AUTOSAR XML (schema 4-2-2)
package /ASW_COM_STD_Package
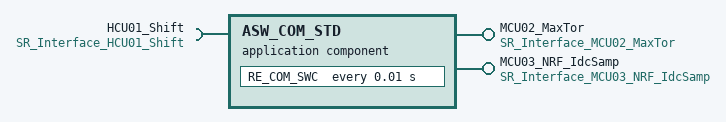
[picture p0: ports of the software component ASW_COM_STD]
  application sw component type ASW_COM_STD
    provide port MCU02_MaxTor: provided-interface=SR_Interface_MCU02_MaxTor
    provide port MCU03_NRF_IdcSamp: provided-interface=SR_Interface_MCU03_NRF_IdcSamp
    require port HCU01_Shift: nonqueued-receiver-com-spec{data-element=HCU01_Shift, alive-timeout=0.3, filter=data-filter-type=ALWAYS}, required-interface=SR_Interface_HCU01_Shift
    behavior ASW_COM_STD_InternalBehavior
      timing event TE_RE_COM_SWC: start-on-event=RE_COM_SWC, period=0.01
      runnable RE_COM_SWC
        data-read-accesses:
          access RA_HCU01_Shift: accessed-variable=HCU01_Shift.HCU01_Shift
        data-write-accesses:
          access WA_MCU02_MaxTor: accessed-variable=MCU02_MaxTor.MCU02_MaxTor
          access WA_MCU03_NRF_IdcSamp: accessed-variable=MCU03_NRF_IdcSamp.MCU03_NRF_IdcSamp
